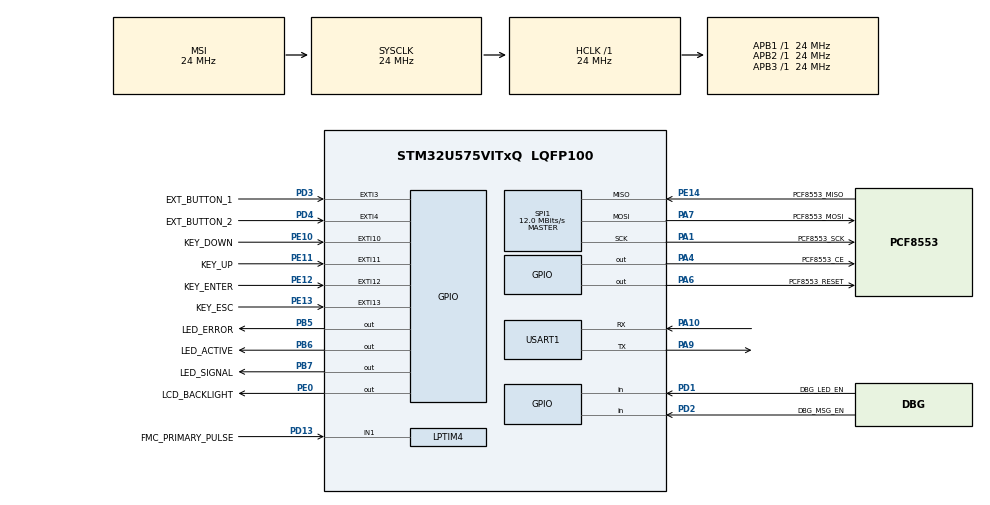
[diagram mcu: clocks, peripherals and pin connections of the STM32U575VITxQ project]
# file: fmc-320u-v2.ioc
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CORTEX_M33_NS.userName=CORTEX_M33
LPTIM1.ClockPrescaler=LPTIM_PRESCALER_DIV16
LPTIM3.ClockPrescaler=LPTIM_PRESCALER_DIV16
LPTIM4.ULPClockPolarity=LPTIM_CLOCKPOLARITY_FALLING
Mcu.Family=STM32U5
Mcu.Name=STM32U575VITxQ
Mcu.Package=LQFP100
NVIC.EXTI10_IRQn=true\:5\:0\:true\:false\:true\:false\:true\:true\:true
NVIC.EXTI11_IRQn=true\:5\:0\:true\:false\:true\:false\:true\:true\:true
NVIC.EXTI12_IRQn=true\:5\:0\:true\:false\:true\:false\:true\:true\:true
NVIC.EXTI13_IRQn=true\:5\:0\:true\:false\:true\:false\:true\:true\:true
NVIC.EXTI3_IRQn=true\:5\:0\:true\:false\:true\:false\:true\:true\:true
NVIC.EXTI4_IRQn=true\:5\:0\:true\:false\:true\:false\:true\:true\:true
NVIC.LPTIM1_IRQn=true\:5\:0\:true\:false\:true\:false\:true\:true\:true
NVIC.PriorityGroup=NVIC_PRIORITYGROUP_4
NVIC.TIM6_IRQn=true\:15\:0\:false\:false\:true\:false\:false\:true\:true
NVIC.TimeBase=TIM6_IRQn
NVIC.TimeBaseIP=TIM6
PA1.GPIO_Label=PCF8553_SCK
PA1.Mode=Full_Duplex_Master
PA1.Signal=SPI1_SCK
PA10.Mode=Asynchronous
PA10.Signal=USART1_RX
PA13\ (JTMS/SWDIO).Mode=Trace_Asynchronous_SW
PA13\ (JTMS/SWDIO).Signal=DEBUG_JTMS-SWDIO
PA14\ (JTCK/SWCLK).Mode=Trace_Asynchronous_SW
PA14\ (JTCK/SWCLK).Signal=DEBUG_JTCK-SWCLK
PA4.GPIO_Label=PCF8553_CE
PA4.Signal=GPIO_Output
PA6.GPIO_Label=PCF8553_RESET
PA6.Signal=GPIO_Output
PA7.GPIO_Label=PCF8553_MOSI
PA7.Mode=Full_Duplex_Master
PA7.Signal=SPI1_MOSI
PA9.Mode=Asynchronous
PA9.Signal=USART1_TX
PB3\ (JTDO/TRACESWO).Mode=Trace_Asynchronous_SW
PB3\ (JTDO/TRACESWO).Signal=DEBUG_JTDO-SWO
PB5.GPIO_Label=LED_ERROR
PB5.Signal=GPIO_Output
PB6.GPIO_Label=LED_ACTIVE
PB6.Signal=GPIO_Output
PB7.GPIO_Label=LED_SIGNAL
PB7.Signal=GPIO_Output
PC14-OSC32_IN\ (PC14).Mode=LSE-External-Oscillator
PC14-OSC32_IN\ (PC14).Signal=RCC_OSC32_IN
PC15-OSC32_OUT\ (PC15).Mode=LSE-External-Oscillator
PC15-OSC32_OUT\ (PC15).Signal=RCC_OSC32_OUT
PD1.GPIO_Label=DBG_LED_EN
PD1.Signal=GPIO_Input
PD13.GPIO_Label=FMC_PRIMARY_PULSE
PD13.Mode=Counts_external_clock_standalone_1X_occur1
PD13.Signal=LPTIM4_IN1
PD2.GPIO_Label=DBG_MSG_EN
PD2.Signal=GPIO_Input
PD3.GPIO_Label=EXT_BUTTON_1
PD3.GPIO_ModeDefaultEXTI=GPIO_MODE_IT_RISING_FALLING
PD3.GPIO_PuPd=GPIO_PULLUP
PD3.Signal=GPXTI3
PD4.GPIO_Label=EXT_BUTTON_2
PD4.GPIO_ModeDefaultEXTI=GPIO_MODE_IT_RISING_FALLING
PD4.GPIO_PuPd=GPIO_PULLUP
PD4.Signal=GPXTI4
PE0.GPIO_Label=LCD_BACKLIGHT
PE0.PinState=GPIO_PIN_SET
PE0.Signal=GPIO_Output
PE10.GPIO_Label=KEY_DOWN
PE10.GPIO_ModeDefaultEXTI=GPIO_MODE_IT_RISING_FALLING
PE10.Signal=GPXTI10
PE11.GPIO_Label=KEY_UP
PE11.GPIO_ModeDefaultEXTI=GPIO_MODE_IT_RISING_FALLING
PE11.Signal=GPXTI11
PE12.GPIO_Label=KEY_ENTER
PE12.GPIO_ModeDefaultEXTI=GPIO_MODE_IT_RISING_FALLING
PE12.Signal=GPXTI12
PE13.GPIO_Label=KEY_ESC
PE13.GPIO_ModeDefaultEXTI=GPIO_MODE_IT_RISING_FALLING
PE13.Signal=GPXTI13
PE14.GPIO_Label=PCF8553_MISO
PE14.Mode=Full_Duplex_Master
PE14.Signal=SPI1_MISO
PWR.PowerMode=PWR_SMPS_SUPPLY
ProjectManager.HeapSize=0x200
ProjectManager.StackSize=0x400
ProjectManager.TargetToolchain=CMake
RCC.ADCFreq_Value=16000000
RCC.AHBFreq_Value=24000000
RCC.APB1Freq_Value=24000000
RCC.APB1TimFreq_Value=24000000
RCC.APB2Freq_Value=24000000
RCC.APB2TimFreq_Value=24000000
RCC.APB3Freq_Value=24000000
RCC.CortexFreq_Value=24000000
RCC.EPOD_VALUE=24000000
RCC.HCLKFreq_Value=24000000
RCC.HSE_VALUE=16000000
RCC.HSI48_VALUE=48000000
RCC.HSI_VALUE=16000000
RCC.LPTIM1CLockSelectionVirtual=RCC_LPTIM1CLKSOURCE_LSE
RCC.LPTIM3CLockSelectionVirtual=RCC_LPTIM34CLKSOURCE_LSE
RCC.LSIDIV_VALUE=32000
RCC.MSIClockRange=RCC_MSIRANGE_1
RCC.MSI_VALUE=24000000
RCC.RTCClockSelection=RCC_RTCCLKSOURCE_LSE
RCC.SYSCLKFreq_VALUE=24000000
RCC.USBFreq_Value=48000000
RCC.VCOOutputFreq_Value=3096000000
SPI1.CalculateBaudRate=12.0 MBits/s
SPI1.DataSize=SPI_DATASIZE_8BIT
SPI1.Direction=SPI_DIRECTION_2LINES
SPI1.Mode=SPI_MODE_MASTER
SPI1.VirtualType=VM_MASTER
THREADX.TX_APP_GENERATE_INIT_CODE=false
THREADX.TX_APP_MEM_POOL_SIZE=16384
THREADX.TX_ENABLE_STACK_CHECKING=1
THREADX.TX_LOW_POWER=1
THREADX.TX_TIMER_THREAD_STACK_SIZE=2048
USART1.VirtualMode-Asynchronous=VM_ASYNC
VP_ICACHE_VS_ICACHE.Mode=DirectMappedCache
VP_LPBAMQUEUE_VS_QUEUE.Mode=QUEUEMODE
VP_LPBAM_VS_SIG1.Mode=SmartRun
VP_LPBAM_VS_SIG4.Mode=LPDMA1
VP_LPTIM1_VS_LPTIM_counterModeInternalClock.Mode=Counts__internal_clock_event_00
VP_LPTIM3_VS_LPTIM_counterModeInternalClock.Mode=Counts__internal_clock_event_00
VP_MEMORYMAP_VS_MEMORYMAP.Mode=CurAppReg
VP_PWR_VS_DBSignals.Mode=DisableDeadBatterySignals
VP_PWR_VS_LPOM.Mode=PowerOptimisation
VP_PWR_VS_SECSignals.Mode=Security/Privilege
VP_RTC_VS_RTC_Activate.Mode=RTC_Enabled
VP_RTC_VS_RTC_WakeUp_intern.Mode=WakeUp
VP_SYS_VS_tim6.Mode=TIM6
VP_THREADX_VS_RTOSJjThreadXJjCoreJjDefault.Mode=Core_Default
VP_THREADX_VS_RTOSJjThreadXJjLow_Power_Support.Mode=Low_Power_Support
board=custom

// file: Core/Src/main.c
/* USER CODE BEGIN Header */
/**
  ******************************************************************************
  * @file           : main.c
  * @brief          : Main program body
  ******************************************************************************
  * @attention
  *
  * Copyright (c) 2026 STMicroelectronics.
  * All rights reserved.
  *
  * This software is licensed under terms that can be found in the LICENSE file
  * in the root directory of this software component.
  * If no LICENSE file comes with this software, it is provided AS-IS.
  *
  ******************************************************************************
  */
/* USER CODE END Header */
#include "app_threadx.h"
#include "main.h"
#include "icache.h"
#include "lptim.h"
#include "rtc.h"
#include "spi.h"
#include "usart.h"

/* USER CODE BEGIN Includes */
#include "fm_debug.h"
/* USER CODE END Includes */

void SystemClock_Config(void);
static void SystemPower_Config(void);

int main(void)
{

  /* MCU Configuration--------------------------------------------------------*/

  /* Reset of all peripherals, Initializes the Flash interface and the Systick. */
  HAL_Init();

  /* Configure the System Power */
  SystemPower_Config();

  /* USER CODE BEGIN SysInit */
  SystemClock_Config();

  /* USER CODE END SysInit */

  /* Initialize all configured peripherals */
  MX_RTC_Init();
  MX_USART1_UART_Init();
  MX_ICACHE_Init();
  MX_SPI1_Init();
  MX_LPTIM1_Init();
  MX_LPTIM4_Init();
  MX_LPTIM3_Init();

  MX_ThreadX_Init();

  /* We should never get here as control is now taken by the scheduler */

  /* Infinite loop */
  while (1)
  {

  }
}

void SystemClock_Config(void)
{
  RCC_OscInitTypeDef RCC_OscInitStruct = {0};
  RCC_ClkInitTypeDef RCC_ClkInitStruct = {0};

  /** Configure the main internal regulator output voltage
  */
  if (HAL_PWREx_ControlVoltageScaling(PWR_REGULATOR_VOLTAGE_SCALE4) != HAL_OK)
  {
    Error_Handler();
  }

  /** Configure LSE Drive Capability
  */
  HAL_PWR_EnableBkUpAccess();
  __HAL_RCC_LSEDRIVE_CONFIG(RCC_LSEDRIVE_LOW);

  /** Initializes the CPU, AHB and APB buses clocks
  */
  RCC_OscInitStruct.OscillatorType = RCC_OSCILLATORTYPE_LSE|RCC_OSCILLATORTYPE_MSI;
  RCC_OscInitStruct.LSEState = RCC_LSE_ON;
  RCC_OscInitStruct.MSIState = RCC_MSI_ON;
  RCC_OscInitStruct.MSICalibrationValue = RCC_MSICALIBRATION_DEFAULT;
  RCC_OscInitStruct.MSIClockRange = RCC_MSIRANGE_1;
  RCC_OscInitStruct.PLL.PLLState = RCC_PLL_NONE;
  if (HAL_RCC_OscConfig(&RCC_OscInitStruct) != HAL_OK)
  {
    Error_Handler();
  }

  /** Initializes the CPU, AHB and APB buses clocks
  */
  RCC_ClkInitStruct.ClockType = RCC_CLOCKTYPE_HCLK|RCC_CLOCKTYPE_SYSCLK
                              |RCC_CLOCKTYPE_PCLK1|RCC_CLOCKTYPE_PCLK2
                              |RCC_CLOCKTYPE_PCLK3;
  RCC_ClkInitStruct.SYSCLKSource = RCC_SYSCLKSOURCE_MSI;
  RCC_ClkInitStruct.AHBCLKDivider = RCC_SYSCLK_DIV1;
  RCC_ClkInitStruct.APB1CLKDivider = RCC_HCLK_DIV1;
  RCC_ClkInitStruct.APB2CLKDivider = RCC_HCLK_DIV1;
  RCC_ClkInitStruct.APB3CLKDivider = RCC_HCLK_DIV1;

  if (HAL_RCC_ClockConfig(&RCC_ClkInitStruct, FLASH_LATENCY_1) != HAL_OK)
  {
    Error_Handler();
  }
}

/**
  * @brief Power Configuration
  * @retval None
  */
static void SystemPower_Config(void)
{

  /*
   * Disable the internal Pull-Up in Dead Battery pins of UCPD peripheral
   */
  HAL_PWREx_DisableUCPDDeadBattery();

  /*
   * Switch to SMPS regulator instead of LDO
   */
  if (HAL_PWREx_ConfigSupply(PWR_SMPS_SUPPLY) != HAL_OK)
  {
    Error_Handler();
  }
}

void HAL_TIM_PeriodElapsedCallback(TIM_HandleTypeDef *htim)
{
  if (htim->Instance == TIM6)
  {
    HAL_IncTick();
  }
}

void Error_Handler(void)
{
  /* USER CODE BEGIN Error_Handler_Debug */
  /* User can add his own implementation to report the HAL error return state */
  __disable_irq();
  FM_DEBUG_PanicMsg("Error_Handler");
  /* USER CODE END Error_Handler_Debug */
}
